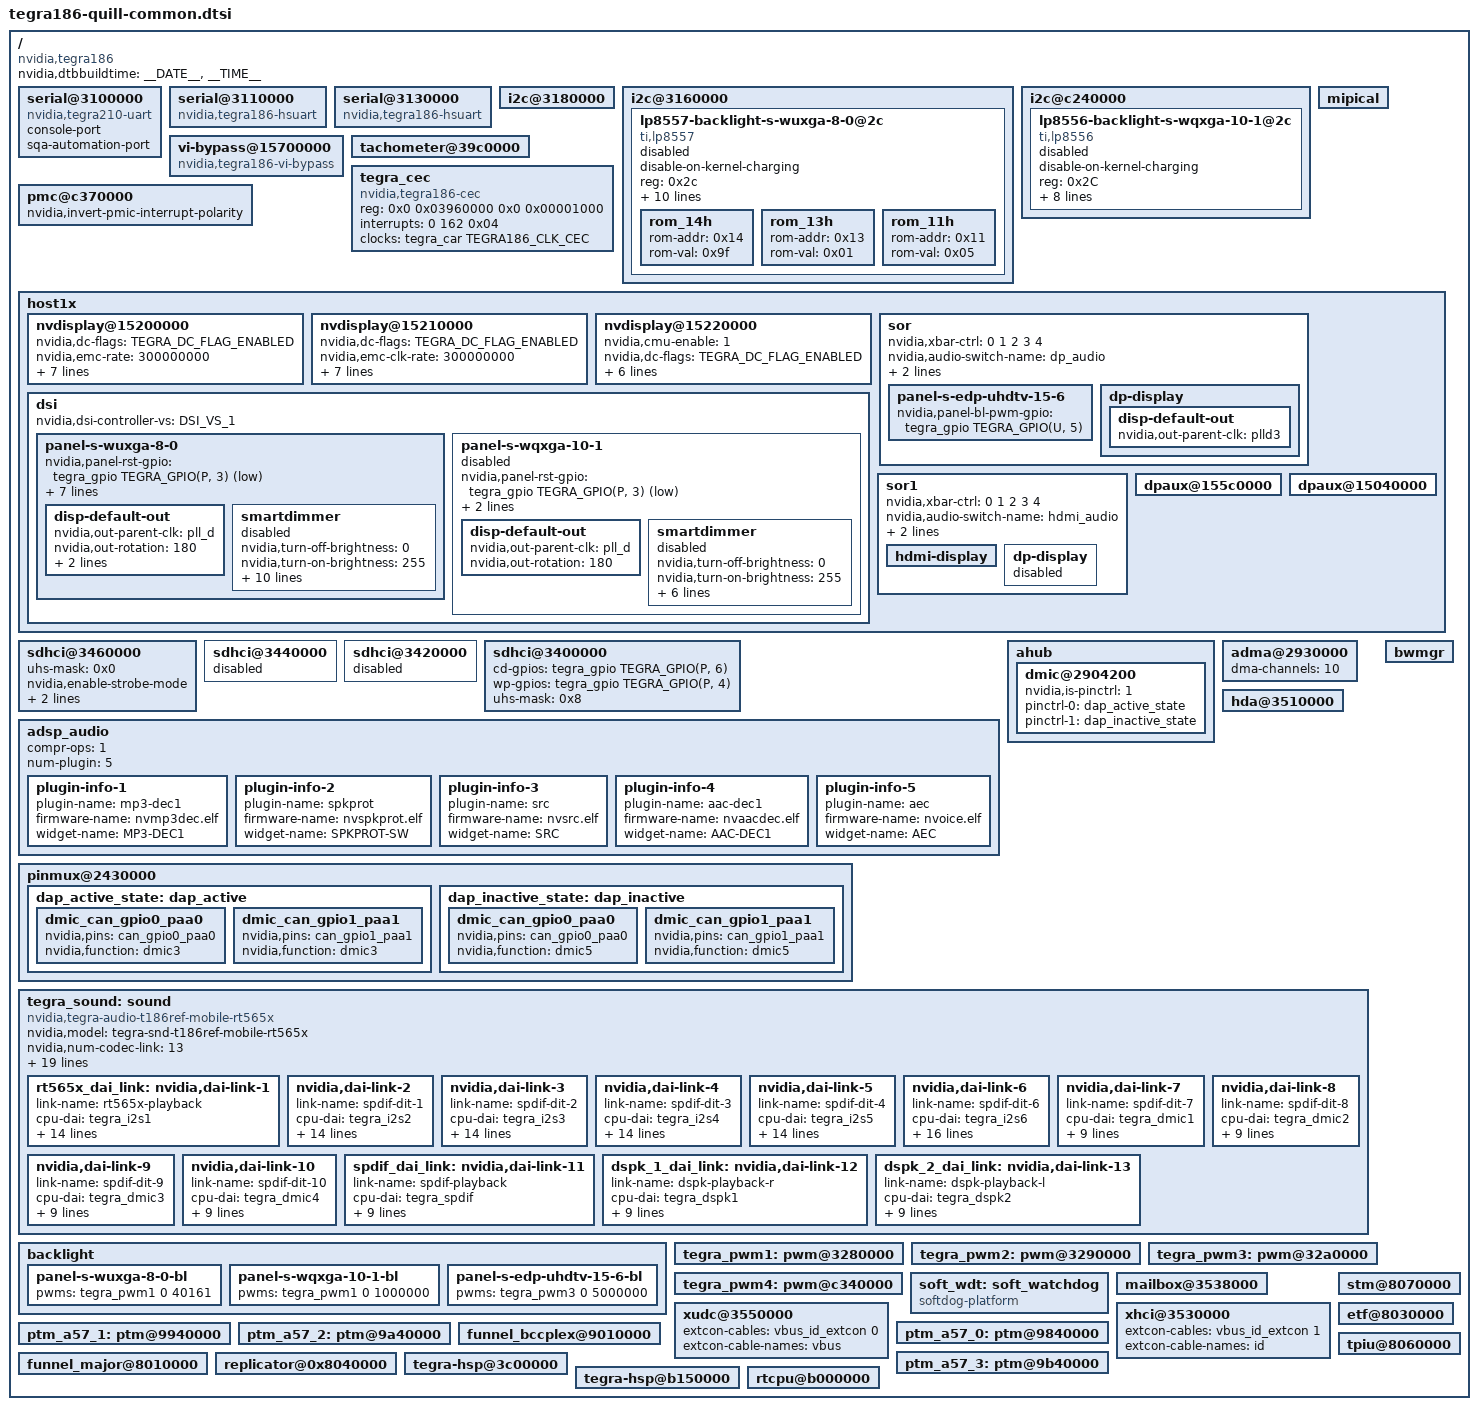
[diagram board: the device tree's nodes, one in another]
/*
 * tegra186-quill-common.dtsi: Quill common dtsi.
 *
 * Copyright (c) 2015-2016, NVIDIA CORPORATION.  All rights reserved.
 *
 * This program is free software; you can redistribute it and/or modify
 * it under the terms of the GNU General Public License as published by
 * the Free Software Foundation; version 2 of the License.
 *
 * This program is distributed in the hope that it will be useful, but WITHOUT
 * ANY WARRANTY; without even the implied warranty of MERCHANTABILITY or
 * FITNESS FOR A PARTICULAR PURPOSE.  See the GNU General Public License for
 * more details.
 */

#include <dt-bindings/types.h>
#include <dt-bindings/gpio/tegra-gpio.h>
/dts-v1/;

/memreserve/ 0x80000000 0x00010000;

#include "tegra186-soc/tegra186-soc-cvm.dtsi"
#include "tegra186-platforms-simple-bus.dtsi"
#include "panel-s-wuxga-8-0.dtsi"
#include "panel-s-wqxga-10-1.dtsi"
#include "tegra186-platforms/tegra186-quill-eqos.dtsi"
#include "tegra186-hdmi.dtsi"
#include "tegra186-dp.dtsi"
#include "panel-s-edp-uhdtv-15-6.dtsi"
#include "tegra186-quill-pwm-fan.dtsi"
#include "tegra186-quill-thermal-fan-est.dtsi"

/ {
        compatible = "nvidia,tegra186";

        nvidia,dtbbuildtime = __DATE__, __TIME__;
        #address-cells = <2>;
        #size-cells = <2>;

	serial@3100000 {
		compatible = "nvidia,tegra210-uart", "nvidia,tegra186-hsuart";
		console-port;
		sqa-automation-port;
		status = "okay";
	};

	serial@3110000 {
		compatible = "nvidia,tegra186-hsuart";
		status = "okay";
	};

	serial@3130000 {
		compatible = "nvidia,tegra186-hsuart";
		dma-names = "tx";
		status = "okay";
	};

	i2c@3180000 {
		status = "okay";
	};

	i2c@3160000 {
		status = "okay";
		lp8557-backlight-s-wuxga-8-0@2c {
			status = "disabled";
			disable-on-kernel-charging;
			compatible = "ti,lp8557";
			reg = <0x2c>;

			bl-name = "pwm-backlight"; /* Match liblights naming expectations */
			init-brt = /bits/ 8 <0xFF>; /* Max brightness */
			dev-ctrl = /bits/ 8 <0x80>; /* PWM, enable standby mode */
			pwm-period = <40161>;

			pwm-names = "lp8557";
			pwms = <&tegra_pwm1 0 40161>;

			bl-measured = < 0 1 2 3 4 5 5 6
					7 8 9 10 11 11 12 13
					14 15 15 16 17 18 19 20
					21 22 22 23 24 25 26 27
					28 29 30 31 31 32 33 34
					35 36 37 37 38 39 40 41
					41 42 43 44 45 46 47 48
					48 49 50 51 52 53 54 54
					55 56 57 58 58 59 60 61
					62 63 64 65 66 67 68 69
					70 71 72 73 74 75 75 76
					77 78 79 80 81 82 83 84
					85 86 87 88 89 90 91 92
					93 94 94 95 96 97 98 99
					100 101 102 104 105 106 107 108
					109 110 111 112 113 114 115 116
					117 118 119 120 121 122 123 125
					126 127 128 129 130 131 132 133
					134 135 136 137 138 139 140 141
					142 143 144 146 147 148 149 150
					151 152 153 154 155 156 157 158
					159 160 161 162 163 164 165 167
					168 169 170 171 172 173 174 175
					176 178 179 180 181 182 183 184
					185 186 187 188 189 190 191 192
					193 194 195 196 197 199 200 201
					202 203 204 205 206 207 208 210
					211 212 213 214 215 216 217 219
					220 221 222 223 225 226 227 228
					229 230 231 233 234 235 236 237
					238 239 240 241 242 244 245 246
					247 248 249 250 251 253 254 255 >;

			bl-curve = < 0 1 1 2 2 3 3 4
					4 5 5 6 7 7 8 8
					9 9 10 10 11 11 12 12
					13 14 14 15 15 16 16 17
					17 18 18 19 20 20 21 21
					22 22 23 23 24 24 25 25
					26 27 27 28 28 29 29 30
					30 31 31 32 33 33 34 34
					35 35 36 36 37 37 38 38
					39 40 40 41 41 42 42 43
					43 44 44 45 46 46 47 47
					48 48 49 49 50 50 51 52
					52 53 53 54 54 55 55 56
					56 57 57 58 59 59 60 60
					61 61 62 62 63 63 64 65
					65 66 66 67 67 68 68 69
					69 70 70 71 72 72 73 73
					74 74 75 75 76 76 77 78
					78 79 79 80 80 81 81 82
					82 83 83 84 85 85 86 86
					87 87 88 88 89 89 90 92
					94 96 97 99 101 103 105 107
					109 110 112 114 116 118 120 122
					123 125 127 129 131 133 134 136
					138 140 142 144 146 147 149 151
					153 155 157 159 160 162 164 166
					168 170 172 173 175 177 179 181
					183 185 186 188 190 192 194 196
					198 199 201 203 205 207 209 211
					212 214 216 218 220 222 223 225
					227 229 231 233 235 236 238 240
					242 244 246 248 249 251 253 255 >;

			/* 5 LED string */
			rom_14h {
				rom-addr = /bits/ 8 <0x14>;
				rom-val = /bits/ 8 <0x9f>;
			};

			/*Boost freq 1MHZ*/
			rom_13h {
				rom-addr = /bits/ 8 <0x13>;
				rom-val = /bits/ 8 <0x01>;
			};

			/*20mA max */
			rom_11h {
				rom-addr = /bits/ 8 <0x11>;
				rom-val = /bits/ 8 <0x05>;
			};
		};
	};

	i2c@c240000 {
		status = "okay";
		lp8556-backlight-s-wqxga-10-1@2c {
			status = "disabled";
			disable-on-kernel-charging;
			compatible = "ti,lp8556";
			reg = <0x2C>;

			bl-name = "pwm-backlight"; /* Match liblights naming expectations */
			init-brt = /bits/ 8 <0xFF>; /* Max brightness */
			dev-ctrl = /bits/ 8 <0x80>; /* PWM, enable standby mode */
			pwm-period = <40161>;

			pwm-names = "lp8556";
			pwms = <&tegra_pwm1 0 40161>;

			bl-measured = < 0 1 2 3 4 5 5 6
					7 8 9 10 11 11 12 13
					14 15 15 16 17 18 19 20
					21 22 22 23 24 25 26 27
					28 29 30 31 31 32 33 34
					35 36 37 37 38 39 40 41
					41 42 43 44 45 46 47 48
					48 49 50 51 52 53 54 54
					55 56 57 58 58 59 60 61
					62 63 64 65 66 67 68 69
					70 71 72 73 74 75 75 76
					77 78 79 80 81 82 83 84
					85 86 87 88 89 90 91 92
					93 94 94 95 96 97 98 99
					100 101 102 104 105 106 107 108
					109 110 111 112 113 114 115 116
					117 118 119 120 121 122 123 125
					126 127 128 129 130 131 132 133
					134 135 136 137 138 139 140 141
					142 143 144 146 147 148 149 150
					151 152 153 154 155 156 157 158
					159 160 161 162 163 164 165 167
					168 169 170 171 172 173 174 175
					176 178 179 180 181 182 183 184
					185 186 187 188 189 190 191 192
					193 194 195 196 197 199 200 201
					202 203 204 205 206 207 208 210
					211 212 213 214 215 216 217 219
					220 221 222 223 225 226 227 228
					229 230 231 233 234 235 236 237
					238 239 240 241 242 244 245 246
					247 248 249 250 251 253 254 255 >;
		};

	};

	vi-bypass@15700000{
		compatible = "nvidia,tegra186-vi-bypass";
		status = "okay";
	};

	tachometer@39c0000 {
		status = "okay";
	};

	tegra_cec {
		status = "okay";
		compatible = "nvidia,tegra186-cec";
		reg = <0x0 0x03960000 0x0 0x00001000>;
		interrupts = <0 162 0x04>;
		clocks = <&tegra_car TEGRA186_CLK_CEC>;
		clock-names = "cec";
	};

	pmc@c370000 {
		nvidia,invert-pmic-interrupt-polarity;
	};

        mipical {
                status = "okay";
        };

	host1x {
		nvdisplay@15200000 {
                        status = "okay";
                        nvidia,dc-flags = <TEGRA_DC_FLAG_ENABLED>;
                        nvidia,emc-rate = <300000000>;
                        nvidia,fb-bpp = <32>;
                        nvidia,fb-flags = <TEGRA_FB_FLIP_ON_PROBE>;
			nvidia,fb-win = <0>;
			win-mask = <0x7>;
			nvidia,dc-ctrlnum = <0>;
			nvidia,dc-or-node = "/host1x/dsi";
			nvidia,cmu-enable = <1>;
                };

		nvdisplay@15210000 {
			status = "okay";
			nvidia,dc-flags = <TEGRA_DC_FLAG_ENABLED>;
			nvidia,emc-clk-rate = <300000000>;
			nvidia,fb-bpp = <32>; /* bits per pixel */
			nvidia,fb-flags = <TEGRA_FB_FLIP_ON_PROBE>;
			nvidia,fb-win = <3>;
			win-mask = <0x38>;
			nvidia,dc-ctrlnum = <1>;
			nvidia,dc-or-node = "/host1x/sor1";
			nvidia,cmu-enable = <1>;
		};

		nvdisplay@15220000 {
			nvidia,cmu-enable = <1>;
		};

		nvdisplay@15220000 {
			status = "okay";
			nvidia,dc-flags = <TEGRA_DC_FLAG_ENABLED>;
			nvidia,emc-clk-rate = <300000000>;
			nvidia,fb-bpp = <32>; /* bits per pixel */
			nvidia,fb-flags = <TEGRA_FB_FLIP_ON_PROBE>;
			win-mask = <0x0>;
			nvidia,dc-ctrlnum = <2>;
			nvidia,dc-or-node = "/host1x/sor";
		};

		dsi {	/* dsi@15300000 */
			nvidia,dsi-controller-vs = <DSI_VS_1>;
			status = "okay";
			panel-s-wuxga-8-0 {
				status = "okay";
				nvidia,panel-rst-gpio = <&tegra_gpio TEGRA_GPIO(P, 3) 1>; /* PP3 */
				nvidia,panel-bl-pwm-gpio = <&tegra_gpio TEGRA_GPIO(U, 0) 1>; /* PU0 */
				nvidia,panel-bl-en-gpio = <&tegra_gpio TEGRA_GPIO(U, 3) 1>; /* PU3 */
				nvidia,panel-en-gpio = <&gpio_i2c_0_77 4 1>; /* tca9539 0x77 Pin 4 */
				nvidia,en-vmm-vpp-with-i2c-config;
				nvidia,default_color_space = <0>;
				disp-default-out {
					nvidia,out-parent-clk = "pll_d";
					nvidia,out-rotation = <180>;
					nvidia,out-xres = <4096>;
					nvidia,out-yres = <2160>;
                                };
				smartdimmer {
					status = "disabled";
					nvidia,turn-off-brightness = <0>;
					nvidia,turn-on-brightness = <255>;
					nvidia,sw-update-delay = <0>;
					nvidia,aggressiveness = <5>;
					nvidia,phase-in-settings = <0>;
					nvidia,phase-in-adjustments = <0>;
					nvidia,sd-window-enable = <0>;
					nvidia,bl-device-name = "pwm-backlight";
					nvidia,gain_table = <
						0x4000 0x4000 0x4000 0x4000 0x4000 0x4000 0x4000 0x4000
						0x4000 0x4000 0x4000 0x4000 0x4000 0x4000 0x4000 0x4000
						0x4000 0x4000 0x4000 0x4000 0x4000 0x4000 0x4000 0x4000
						0x4000 0x4000 0x4000 0x4000 0x4000 0x4000 0x4000 0x4000
						0x4144 0x4144 0x4144 0x4144 0x4144 0x4144 0x4144 0x4144
						0x4144 0x4144 0x4144 0x4144 0x4144 0x4144 0x4144 0x4144
						0x4144 0x4144 0x4144 0x4144 0x4144 0x4144 0x4144 0x4144
						0x4144 0x4144 0x4144 0x4144 0x4144 0x4144 0x4144 0x4144
						0x428c 0x428c 0x428c 0x428c 0x428c 0x428c 0x428c 0x428c
						0x428c 0x428c 0x428c 0x428c 0x428c 0x428c 0x428c 0x428c
						0x428c 0x428c 0x428c 0x428c 0x428c 0x428c 0x428c 0x428c
						0x428c 0x428c 0x428c 0x428c 0x428c 0x428c 0x428c 0x4250
						0x43d4 0x43d4 0x43d4 0x43d4 0x43d4 0x43d4 0x43d4 0x43d4
						0x43d4 0x43d4 0x43d4 0x43d4 0x43d4 0x43d4 0x43d4 0x43d4
						0x43d4 0x43d4 0x43d4 0x43d4 0x43d4 0x43d4 0x43d4 0x43d4
						0x43d4 0x43d4 0x43d4 0x43d4 0x43d4 0x43d4 0x43d4 0x42b4
						0x451c 0x451c 0x451c 0x451c 0x451c 0x451c 0x451c 0x451c
						0x451c 0x451c 0x451c 0x451c 0x451c 0x451c 0x451c 0x451c
						0x451c 0x451c 0x451c 0x451c 0x451c 0x451c 0x451c 0x451c
						0x451c 0x451c 0x451c 0x451c 0x451c 0x451c 0x44e0 0x4304
						0x4664 0x4664 0x4664 0x4664 0x4664 0x4664 0x4664 0x4664
						0x4664 0x4664 0x4664 0x4664 0x4664 0x4664 0x4664 0x4664
						0x4664 0x4664 0x4664 0x4664 0x4664 0x4664 0x4664 0x4664
						0x4664 0x4664 0x4664 0x4664 0x4664 0x4660 0x4570 0x4318
						0x47ac 0x47ac 0x47ac 0x47ac 0x47ac 0x47ac 0x47ac 0x47ac
						0x47ac 0x47ac 0x47ac 0x47ac 0x47ac 0x47ac 0x47ac 0x47ac
						0x47ac 0x47ac 0x47ac 0x47ac 0x47ac 0x47ac 0x47ac 0x47ac
						0x47ac 0x47ac 0x47ac 0x47ac 0x47ac 0x4768 0x45e8 0x433c
						0x48f4 0x48f4 0x48f4 0x48f4 0x48f4 0x48f4 0x48f4 0x48f4
						0x48f4 0x48f4 0x48f4 0x48f4 0x48f4 0x48f4 0x48f4 0x48f4
						0x48f4 0x48f4 0x48f4 0x48f4 0x48f4 0x48f4 0x48f4 0x48f4
						0x48f4 0x48f4 0x48f4 0x48f4 0x48f0 0x482c 0x4644 0x4354
						0x4a3c 0x4a3c 0x4a3c 0x4a3c 0x4a3c 0x4a3c 0x4a3c 0x4a3c
						0x4a3c 0x4a3c 0x4a3c 0x4a3c 0x4a3c 0x4a3c 0x4a3c 0x4a3c
						0x4a3c 0x4a3c 0x4a3c 0x4a3c 0x4a3c 0x4a3c 0x4a3c 0x4a3c
						0x4a3c 0x4a3c 0x4a3c 0x4a3c 0x4a00 0x48c4 0x4688 0x4368
						0x4b84 0x4b84 0x4b84 0x4b84 0x4b84 0x4b84 0x4b84 0x4b84
						0x4b84 0x4b84 0x4b84 0x4b84 0x4b84 0x4b84 0x4b84 0x4b84
						0x4b84 0x4b84 0x4b84 0x4b84 0x4b84 0x4b84 0x4b84 0x4b84
						0x4b84 0x4b84 0x4b84 0x4b84 0x4af4 0x4960 0x46e0 0x4388
						0x4ccc 0x4ccc 0x4ccc 0x4ccc 0x4ccc 0x4ccc 0x4ccc 0x4ccc
						0x4ccc 0x4ccc 0x4ccc 0x4ccc 0x4ccc 0x4ccc 0x4ccc 0x4ccc
						0x4ccc 0x4ccc 0x4ccc 0x4ccc 0x4ccc 0x4ccc 0x4ccc 0x4ccc
						0x4ccc 0x4ccc 0x4ccc 0x4ca8 0x4ba8 0x49c0 0x4708 0x4390
						0x4e14 0x4e14 0x4e14 0x4e14 0x4e14 0x4e14 0x4e14 0x4e14
						0x4e14 0x4e14 0x4e14 0x4e14 0x4e14 0x4e14 0x4e14 0x4e14
						0x4e14 0x4e14 0x4e14 0x4e14 0x4e14 0x4e14 0x4e14 0x4e14
						0x4e14 0x4e14 0x4e14 0x4db0 0x4c60 0x4a34 0x4748 0x43ac
						0x4f5c 0x4f5c 0x4f5c 0x4f5c 0x4f5c 0x4f5c 0x4f5c 0x4f5c
						0x4f5c 0x4f5c 0x4f5c 0x4f5c 0x4f5c 0x4f5c 0x4f5c 0x4f5c
						0x4f5c 0x4f5c 0x4f5c 0x4f5c 0x4f5c 0x4f5c 0x4f5c 0x4f5c
						0x4f5c 0x4f5c 0x4f48 0x4e78 0x4cd4 0x4a6c 0x475c 0x43ac
						0x50a0 0x50a0 0x50a0 0x50a0 0x50a0 0x50a0 0x50a0 0x50a0
						0x50a0 0x50a0 0x50a0 0x50a0 0x50a0 0x50a0 0x50a0 0x50a0
						0x50a0 0x50a0 0x50a0 0x50a0 0x50a0 0x50a0 0x50a0 0x50a0
						0x50a0 0x50a0 0x5060 0x4f44 0x4d60 0x4ac4 0x478c 0x43c0
						0x51e8 0x51e8 0x51e8 0x51e8 0x51e8 0x51e8 0x51e8 0x51e8
						0x51e8 0x51e8 0x51e8 0x51e8 0x51e8 0x51e8 0x51e8 0x51e8
						0x51e8 0x51e8 0x51e8 0x51e8 0x51e8 0x51e8 0x51e8 0x51e8
						0x51e8 0x51e8 0x5158 0x4ff8 0x4dd8 0x4b14 0x47b4 0x43d0
						0x5330 0x5330 0x5330 0x5330 0x5330 0x5330 0x5330 0x5330
						0x5330 0x5330 0x5330 0x5330 0x5330 0x5330 0x5330 0x5330
						0x5330 0x5330 0x5330 0x5330 0x5330 0x5330 0x5330 0x5330
						0x5330 0x5314 0x5238 0x5098 0x4e44 0x4b54 0x47d8 0x43dc
						0x5478 0x5478 0x5478 0x5478 0x5478 0x5478 0x5478 0x5478
						0x5478 0x5478 0x5478 0x5478 0x5478 0x5478 0x5478 0x5478
						0x5478 0x5478 0x5478 0x5478 0x5478 0x5478 0x5478 0x5478
						0x5478 0x5424 0x5300 0x5124 0x4ea4 0x4b90 0x47f8 0x43e8
						0x55c0 0x55c0 0x55c0 0x55c0 0x55c0 0x55c0 0x55c0 0x55c0
						0x55c0 0x55c0 0x55c0 0x55c0 0x55c0 0x55c0 0x55c0 0x55c0
						0x55c0 0x55c0 0x55c0 0x55c0 0x55c0 0x55c0 0x55c0 0x55c0
						0x55b8 0x5518 0x53b4 0x51a4 0x4ef8 0x4bc4 0x4814 0x43f0
						0x5708 0x5708 0x5708 0x5708 0x5708 0x5708 0x5708 0x5708
						0x5708 0x5708 0x5708 0x5708 0x5708 0x5708 0x5708 0x5708
						0x5708 0x5708 0x5708 0x5708 0x5708 0x5708 0x5708 0x5708
						0x56dc 0x55f4 0x5458 0x5214 0x4f44 0x4bf0 0x4828 0x43f8
						0x5850 0x5850 0x5850 0x5850 0x5850 0x5850 0x5850 0x5850
						0x5850 0x5850 0x5850 0x5850 0x5850 0x5850 0x5850 0x5850
						0x5850 0x5850 0x5850 0x5850 0x5850 0x5850 0x5850 0x5850
						0x57e8 0x56bc 0x54e8 0x527c 0x4f88 0x4c18 0x483c 0x4400
						0x5998 0x5998 0x5998 0x5998 0x5998 0x5998 0x5998 0x5998
						0x5998 0x5998 0x5998 0x5998 0x5998 0x5998 0x5998 0x5998
						0x5998 0x5998 0x5998 0x5998 0x5998 0x5998 0x5998 0x5990
						0x58f4 0x579c 0x559c 0x5308 0x4ff4 0x4c64 0x486c 0x4414
						0x5ae0 0x5ae0 0x5ae0 0x5ae0 0x5ae0 0x5ae0 0x5ae0 0x5ae0
						0x5ae0 0x5ae0 0x5ae0 0x5ae0 0x5ae0 0x5ae0 0x5ae0 0x5ae0
						0x5ae0 0x5ae0 0x5ae0 0x5ae0 0x5ae0 0x5ae0 0x5ae0 0x5ab8
						0x59d4 0x5840 0x5614 0x5358 0x5024 0x4c80 0x4878 0x4418
						0x5c28 0x5c28 0x5c28 0x5c28 0x5c28 0x5c28 0x5c28 0x5c28
						0x5c28 0x5c28 0x5c28 0x5c28 0x5c28 0x5c28 0x5c28 0x5c28
						0x5c28 0x5c28 0x5c28 0x5c28 0x5c28 0x5c28 0x5c28 0x5bd8
						0x5ac4 0x5908 0x56b4 0x53d8 0x5084 0x4cc4 0x48a4 0x4428
						0x5d70 0x5d70 0x5d70 0x5d70 0x5d70 0x5d70 0x5d70 0x5d70
						0x5d70 0x5d70 0x5d70 0x5d70 0x5d70 0x5d70 0x5d70 0x5d70
						0x5d70 0x5d70 0x5d70 0x5d70 0x5d70 0x5d70 0x5d68 0x5cd0
						0x5b80 0x5990 0x5714 0x5418 0x50a8 0x4cd8 0x48ac 0x442c
						0x5eb8 0x5eb8 0x5eb8 0x5eb8 0x5eb8 0x5eb8 0x5eb8 0x5eb8
						0x5eb8 0x5eb8 0x5eb8 0x5eb8 0x5eb8 0x5eb8 0x5eb8 0x5eb8
						0x5eb8 0x5eb8 0x5eb8 0x5eb8 0x5eb8 0x5eb8 0x5e9c 0x5dd4
						0x5c58 0x5a40 0x57a0 0x5484 0x50fc 0x4d10 0x48cc 0x443c
						0x6000 0x6000 0x6000 0x6000 0x6000 0x6000 0x6000 0x6000
						0x6000 0x6000 0x6000 0x6000 0x6000 0x6000 0x6000 0x6000
						0x6000 0x6000 0x6000 0x6000 0x6000 0x6000 0x5fc4 0x5ecc
						0x5d24 0x5ae8 0x5828 0x54ec 0x514c 0x4d48 0x48f0 0x4448
						0x6144 0x6144 0x6144 0x6144 0x6144 0x6144 0x6144 0x6144
						0x6144 0x6144 0x6144 0x6144 0x6144 0x6144 0x6144 0x6144
						0x6144 0x6144 0x6144 0x6144 0x6144 0x6144 0x60c4 0x5f8c
						0x5db4 0x5b50 0x586c 0x5518 0x5160 0x4d50 0x48f0 0x4448
						0x628c 0x628c 0x628c 0x628c 0x628c 0x628c 0x628c 0x628c
						0x628c 0x628c 0x628c 0x628c 0x628c 0x628c 0x628c 0x628c
						0x628c 0x628c 0x628c 0x628c 0x628c 0x6280 0x61cc 0x606c
						0x5e6c 0x5be4 0x58e0 0x5574 0x51a4 0x4d80 0x490c 0x4454
						0x63d4 0x63d4 0x63d4 0x63d4 0x63d4 0x63d4 0x63d4 0x63d4
						0x63d4 0x63d4 0x63d4 0x63d4 0x63d4 0x63d4 0x63d4 0x63d4
						0x63d4 0x63d4 0x63d4 0x63d4 0x63d4 0x63ac 0x62cc 0x6140
						0x5f1c 0x5c70 0x5950 0x55cc 0x51e4 0x4dac 0x4928 0x4460
						0x651c 0x651c 0x651c 0x651c 0x651c 0x651c 0x651c 0x651c
						0x651c 0x651c 0x651c 0x651c 0x651c 0x651c 0x651c 0x651c
						0x651c 0x651c 0x651c 0x651c 0x651c 0x64cc 0x63c0 0x6208
						0x5fc0 0x5cf8 0x59bc 0x561c 0x5220 0x4dd4 0x4940 0x446c
						0x6664 0x6664 0x6664 0x6664 0x6664 0x6664 0x6664 0x6664
						0x6664 0x6664 0x6664 0x6664 0x6664 0x6664 0x6664 0x6664
						0x6664 0x6664 0x6664 0x6664 0x6664 0x65e0 0x64a4 0x62c8
						0x605c 0x5d78 0x5a20 0x5668 0x525c 0x4dfc 0x4958 0x4474
						0x67ac 0x67ac 0x67ac 0x67ac 0x67ac 0x67ac 0x67ac 0x67ac
						0x67ac 0x67ac 0x67ac 0x67ac 0x67ac 0x67ac 0x67ac 0x67ac
						0x67ac 0x67ac 0x67ac 0x67ac 0x679c 0x66e8 0x6584 0x6380
						0x60f4 0x5df0 0x5a80 0x56b0 0x5290 0x4e20 0x4970 0x4480
						0x68f4 0x68f4 0x68f4 0x68f4 0x68f4 0x68f4 0x68f4 0x68f4
						0x68f4 0x68f4 0x68f4 0x68f4 0x68f4 0x68f4 0x68f4 0x68f4
						0x68f4 0x68f4 0x68f4 0x68f4 0x68c8 0x67e8 0x6654 0x642c
						0x6180 0x5e60 0x5ad8 0x56f4 0x52c0 0x4e44 0x4984 0x4488
						0x6a3c 0x6a3c 0x6a3c 0x6a3c 0x6a3c 0x6a3c 0x6a3c 0x6a3c
						0x6a3c 0x6a3c 0x6a3c 0x6a3c 0x6a3c 0x6a3c 0x6a3c 0x6a3c
						0x6a3c 0x6a3c 0x6a3c 0x6a3c 0x69ec 0x68d8 0x6720 0x64d4
						0x6208 0x5ecc 0x5b2c 0x5734 0x52f0 0x4e60 0x4994 0x4490
						0x6b84 0x6b84 0x6b84 0x6b84 0x6b84 0x6b84 0x6b84 0x6b84
						0x6b84 0x6b84 0x6b84 0x6b84 0x6b84 0x6b84 0x6b84 0x6b84
						0x6b84 0x6b84 0x6b84 0x6b80 0x6b00 0x69c0 0x67e0 0x6570
						0x6288 0x5f30 0x5b7c 0x5770 0x531c 0x4e80 0x49a8 0x4494
						0x6ccc 0x6ccc 0x6ccc 0x6ccc 0x6ccc 0x6ccc 0x6ccc 0x6ccc
						0x6ccc 0x6ccc 0x6ccc 0x6ccc 0x6ccc 0x6ccc 0x6ccc 0x6ccc
						0x6ccc 0x6ccc 0x6ccc 0x6cc4 0x6c24 0x6acc 0x68d0 0x6648
						0x6344 0x5fd8 0x5c08 0x57e4 0x5378 0x4ec4 0x49d4 0x44ac
						0x6e14 0x6e14 0x6e14 0x6e14 0x6e14 0x6e14 0x6e14 0x6e14
						0x6e14 0x6e14 0x6e14 0x6e14 0x6e14 0x6e14 0x6e14 0x6e14
						0x6e14 0x6e14 0x6e14 0x6df8 0x6d28 0x6ba0 0x6980 0x66d8
						0x63b8 0x6034 0x5c50 0x5818 0x539c 0x4edc 0x49e0 0x44b0
						0x6f5c 0x6f5c 0x6f5c 0x6f5c 0x6f5c 0x6f5c 0x6f5c 0x6f5c
						0x6f5c 0x6f5c 0x6f5c 0x6f5c 0x6f5c 0x6f5c 0x6f5c 0x6f5c
						0x6f5c 0x6f5c 0x6f5c 0x6f1c 0x6e1c 0x6c6c 0x6a28 0x6760
						0x6428 0x6088 0x5c90 0x584c 0x53c0 0x4ef4 0x49ec 0x44b4
						0x70a0 0x70a0 0x70a0 0x70a0 0x70a0 0x70a0 0x70a0 0x70a0
						0x70a0 0x70a0 0x70a0 0x70a0 0x70a0 0x70a0 0x70a0 0x70a0
						0x70a0 0x70a0 0x70a0 0x7034 0x6f04 0x6d30 0x6ac8 0x67e0
						0x648c 0x60d8 0x5cd0 0x5878 0x53e0 0x4f08 0x49f8 0x44bc
						0x71e8 0x71e8 0x71e8 0x71e8 0x71e8 0x71e8 0x71e8 0x71e8
						0x71e8 0x71e8 0x71e8 0x71e8 0x71e8 0x71e8 0x71e8 0x71e8
						0x71e8 0x71e8 0x71e8 0x7160 0x7014 0x6e24 0x6ba4 0x68a4
						0x6538 0x616c 0x5d4c 0x58e0 0x5430 0x4f44 0x4a20 0x44cc
						0x7330 0x7330 0x7330 0x7330 0x7330 0x7330 0x7330 0x7330
						0x7330 0x7330 0x7330 0x7330 0x7330 0x7330 0x7330 0x7330
						0x7330 0x7330 0x7320 0x7264 0x70ec 0x6ed4 0x6c34 0x6918
						0x6594 0x61b4 0x5d84 0x5908 0x544c 0x4f54 0x4a2c 0x44d0
						0x7478 0x7478 0x7478 0x7478 0x7478 0x7478 0x7478 0x7478
						0x7478 0x7478 0x7478 0x7478 0x7478 0x7478 0x7478 0x7478
						0x7478 0x7478 0x745c 0x7384 0x71f0 0x6fc0 0x6d04 0x69d4
						0x6638 0x6244 0x5dfc 0x5968 0x5498 0x4f90 0x4a50 0x44e0
						0x75c0 0x75c0 0x75c0 0x75c0 0x75c0 0x75c0 0x75c0 0x75c0
						0x75c0 0x75c0 0x75c0 0x75c0 0x75c0 0x75c0 0x75c0 0x75c0
						0x75c0 0x75c0 0x7580 0x7474 0x72b8 0x7064 0x6d88 0x6a3c
						0x668c 0x6280 0x5e28 0x598c 0x54b0 0x4f9c 0x4a58 0x44e4
						0x7708 0x7708 0x7708 0x7708 0x7708 0x7708 0x7708 0x7708
						0x7708 0x7708 0x7708 0x7708 0x7708 0x7708 0x7708 0x7708
						0x7708 0x7708 0x76b0 0x758c 0x73b4 0x7144 0x6e54 0x6af0
						0x6728 0x6308 0x5e9c 0x59e8 0x54f8 0x4fd4 0x4a78 0x44f4
						0x7850 0x7850 0x7850 0x7850 0x7850 0x7850 0x7850 0x7850
						0x7850 0x7850 0x7850 0x7850 0x7850 0x7850 0x7850 0x7850
						0x7850 0x7850 0x77c0 0x766c 0x746c 0x71d8 0x6ec8 0x6b4c
						0x6770 0x6340 0x5ec4 0x5a04 0x550c 0x4fdc 0x4a80 0x44f8
						0x7998 0x7998 0x7998 0x7998 0x7998 0x7998 0x7998 0x7998
						0x7998 0x7998 0x7998 0x7998 0x7998 0x7998 0x7998 0x7998
						0x7998 0x7990 0x78e4 0x7774 0x755c 0x72b0 0x6f88 0x6bf8
						0x6804 0x63c0 0x5f30 0x5a5c 0x5550 0x5010 0x4aa0 0x4504
						0x7ae0 0x7ae0 0x7ae0 0x7ae0 0x7ae0 0x7ae0 0x7ae0 0x7ae0
						0x7ae0 0x7ae0 0x7ae0 0x7ae0 0x7ae0 0x7ae0 0x7ae0 0x7ae0
						0x7ae0 0x7ac0 0x79e0 0x7844 0x7604 0x7338 0x6ff4 0x6c48
						0x6844 0x63ec 0x5f50 0x5a74 0x5560 0x5018 0x4aa4 0x4508
						0x7c28 0x7c28 0x7c28 0x7c28 0x7c28 0x7c28 0x7c28 0x7c28
						0x7c28 0x7c28 0x7c28 0x7c28 0x7c28 0x7c28 0x7c28 0x7c28
						0x7c28 0x7bf8 0x7afc 0x7940 0x76e8 0x7404 0x70ac 0x6cec
						0x68d0 0x6468 0x5fb8 0x5ac8 0x55a0 0x5048 0x4ac4 0x4514
						0x7d70 0x7d70 0x7d70 0x7d70 0x7d70 0x7d70 0x7d70 0x7d70
						0x7d70 0x7d70 0x7d70 0x7d70 0x7d70 0x7d70 0x7d70 0x7d70
						0x7d70 0x7d2c 0x7c10 0x7a3c 0x77cc 0x74d0 0x7160 0x6d8c
						0x695c 0x64dc 0x601c 0x5b18 0x55e0 0x5078 0x4ae0 0x4524
						0x7eb8 0x7eb8 0x7eb8 0x7eb8 0x7eb8 0x7eb8 0x7eb8 0x7eb8
						0x7eb8 0x7eb8 0x7eb8 0x7eb8 0x7eb8 0x7eb8 0x7eb8 0x7eb8
						0x7eb8 0x7e40 0x7cf4 0x7af4 0x785c 0x7544 0x71bc 0x6dd0
						0x6990 0x6504 0x6034 0x5b28 0x55ec 0x507c 0x4ae4 0x4524
						0x8000 0x8000 0x8000 0x8000 0x8000 0x8000 0x8000 0x8000
						0x8000 0x8000 0x8000 0x8000 0x8000 0x8000 0x8000 0x8000
						0x7ffc 0x7f68 0x7e00 0x7be4 0x7938 0x7608 0x7268 0x6e68
						0x6a14 0x6574 0x6094 0x5b78 0x5628 0x50a8 0x4b00 0x4530
					>;
					nvidia,backlight_table = <
						255 243 232 222 212 203 194 186 179 171 165 158 152
						146 141 136 131 126 122 118 114 110 106 103 100 96
						93 90 88 85 83 80 78 76 73 71 69 67 66 64 62 61 59
						58 56 55 53 52 51 49 48
					>;
				};
			};
			panel-s-wqxga-10-1 {
				status = "disabled";
				nvidia,panel-rst-gpio = <&tegra_gpio TEGRA_GPIO(P, 3) 1>; /* PP3 */
				nvidia,panel-bl-pwm-gpio = <&tegra_gpio TEGRA_GPIO(U, 0) 1>; /* PU0 */
				disp-default-out {
					nvidia,out-parent-clk = "pll_d";
					nvidia,out-rotation = <180>;
				};
				smartdimmer {
					status = "disabled";
					nvidia,turn-off-brightness = <0>;
					nvidia,turn-on-brightness = <255>;
					nvidia,sw-update-delay = <0>;
					nvidia,aggressiveness = <5>;
					nvidia,phase-in-settings = <0>;
					nvidia,phase-in-adjustments = <0>;
					nvidia,sd-window-enable = <0>;
					nvidia,bl-device-name = "pwm-backlight";
				};
			};
		};

		sor{
			status = "okay";
			nvidia,xbar-ctrl = <0 1 2 3 4>;
			nvidia,audio-switch-name = "dp_audio";
			nvidia,hpd-gpio = <&tegra_gpio TEGRA_GPIO(P, 0) GPIO_ACTIVE_LOW>;
			panel-s-edp-uhdtv-15-6 {
				nvidia,panel-bl-pwm-gpio = <&tegra_gpio TEGRA_GPIO(U, 5) 0>;
			};

			dp-display {
				disp-default-out {
					nvidia,out-parent-clk = "plld3";
				};
			};
		};
		sor1 {
			status = "okay";
			nvidia,xbar-ctrl = <0 1 2 3 4>;
			nvidia,audio-switch-name = "hdmi_audio";
			nvidia,hpd-gpio = <&tegra_gpio TEGRA_GPIO(P, 1) GPIO_ACTIVE_LOW>;
			hdmi-display {
				status = "okay";
			};

			dp-display {
				status = "disabled";
			};
		};
		dpaux@155c0000 {
			status = "okay";
		};
		dpaux@15040000 {
			status = "okay";
		};
	};

	sdhci@3460000 {
		uhs-mask = <0x0>; /*enable HS400 mode*/
		nvidia,enable-strobe-mode;
		nvidia,en-periodic-cflush;
		nvidia,periodic-cflush-to = <100>;
		status = "okay";
	};

	sdhci@3440000 {
		status = "disabled";
	};

	sdhci@3420000 {
		status = "disabled";
	};

	sdhci@3400000 {
		cd-gpios = <&tegra_gpio TEGRA_GPIO(P, 6) 0>;
		wp-gpios = <&tegra_gpio TEGRA_GPIO(P, 4) 0>;
		uhs-mask = <0x8>;
		status = "okay";
	};

	adsp_audio {
		compr-ops = <1>;
		num-plugin = <5>;
		plugin-info-1 {
			plugin-name = "mp3-dec1";
			firmware-name = "nvmp3dec.elf";
			widget-name = "MP3-DEC1";
		};
		plugin-info-2 {
			plugin-name = "spkprot";
			firmware-name = "nvspkprot.elf";
			widget-name = "SPKPROT-SW";
		};
		plugin-info-3 {
			plugin-name = "src";
			firmware-name = "nvsrc.elf";
			widget-name = "SRC";
		};
		plugin-info-4 {
			plugin-name = "aac-dec1";
			firmware-name = "nvaacdec.elf";
			widget-name = "AAC-DEC1";
		};
		plugin-info-5 {
			plugin-name = "aec";
			firmware-name = "nvoice.elf";
			widget-name = "AEC";
		};
	};

	pinmux@2430000 {
		dap_active_state: dap_active {
			dmic_can_gpio0_paa0 {
				nvidia,pins = "can_gpio0_paa0";
				nvidia,function = "dmic3";
			};
			dmic_can_gpio1_paa1 {
				nvidia,pins = "can_gpio1_paa1";
				nvidia,function = "dmic3";
			};
		};
		dap_inactive_state: dap_inactive {
			dmic_can_gpio0_paa0 {
				nvidia,pins = "can_gpio0_paa0";
				nvidia,function = "dmic5";
			};
			dmic_can_gpio1_paa1 {
				nvidia,pins = "can_gpio1_paa1";
				nvidia,function = "dmic5";
			};
		};
	};

	ahub {
		dmic@2904200 {
			nvidia,is-pinctrl = <1>;
			pinctrl-names = "dap_active", "dap_inactive";
			pinctrl-0 = <&dap_active_state>;
			pinctrl-1 = <&dap_inactive_state>;
		};
	};

	adma@2930000 {
		dma-channels = <10>;
	};

	hda@3510000 {
		status = "okay";
       };

	tegra_sound: sound {
		compatible = "nvidia,tegra-audio-t186ref-mobile-rt565x";
		nvidia,model = "tegra-snd-t186ref-mobile-rt565x";
		nvidia,num-codec-link = <13>;
		nvidia,num-clk = <8>;
		nvidia,clk-rates = < 270950400	/* PLLA_x11025_RATE */
				     11289600	/* AUD_MCLK_x11025_RATE */
				     45158400	/* PLLA_OUT0_x11025_RATE */
				     45158400	/* AHUB_x11025_RATE */
				     245760000  /* PLLA_x8000_RATE */
				     12288000	/* AUD_MCLK_x8000_RATE */
				     49152000	/* PLLA_OUT0_x8000_RATE */
				     49152000 >;/* AHUB_x8000_RATE */
		clocks = <&tegra_car TEGRA186_CLK_PLLP_OUT0>,
			<&tegra_car TEGRA186_CLK_PLLA>,
			<&tegra_car TEGRA186_CLK_PLL_A_OUT0>,
			<&tegra_car TEGRA186_CLK_AHUB>,
			<&tegra_car TEGRA186_CLK_CLK_M>,
			<&tegra_car TEGRA186_CLK_AUD_MCLK>;
		clock-names = "pll_p_out1", "pll_a", "pll_a_out0", "ahub",
				"clk_m", "extern1";
		resets = <&tegra_car TEGRA186_RESET_AUD_MCLK>;
		reset-names = "extern1_rst";

		status = "okay";
		nvidia,audio-routing =
			"x Headphone",		"x OUT",
			"x IN",			"x Mic",
			"y Headphone",		"y OUT",
			"y IN",			"y Mic",
			"z IN",			"z OUT",
			"m Headphone",		"m OUT",
			"m IN",			"m Mic",
			"n Headphone",		"n OUT",
			"n IN",			"n Mic",
			"o Headphone",		"o OUT",
			"o IN",			"o Mic",
			"a IN",			"a Mic",
			"b IN",			"b Mic",
			"c IN",			"c Mic",
			"d IN",			"d Mic",
			"e Headphone",		"e OUT",
			"e IN",			"e Mic",
			"d1 Headphone",		"d1 OUT",
			"d2 Headphone",		"d2 OUT";

		nvidia,xbar = <&tegra_axbar>;

		rt565x_dai_link: nvidia,dai-link-1 {
			link-name = "rt565x-playback";
			cpu-dai = <&tegra_i2s1>;
			codec-dai = <&spdif_dit0>;
			cpu-dai-name = "I2S1";
			codec-dai-name = "dit-hifi";
			format = "i2s";
			bitclock-slave;
			frame-slave;
			bitclock-noninversion;
			frame-noninversion;
			bit-format = "s16_le";
			bclk_ratio = <0>;
			srate = <48000>;
			num-channel = <2>;
			ignore_suspend;
			name-prefix = "x";
			status = "okay";
		};
		nvidia,dai-link-2 {
			link-name = "spdif-dit-1";
			cpu-dai = <&tegra_i2s2>;
			codec-dai = <&spdif_dit1>;
			cpu-dai-name = "I2S2";
			codec-dai-name = "dit-hifi";
			format = "i2s";
			bitclock-slave;
			frame-slave;
			bitclock-noninversion;
			frame-noninversion;
			bit-format = "s16_le";
			bclk_ratio = <1>;
			srate = <48000>;
			num-channel = <2>;
			ignore_suspend;
			name-prefix = "y";
			status = "okay";
		};
		nvidia,dai-link-3 {
			link-name = "spdif-dit-2";
			cpu-dai = <&tegra_i2s3>;
			codec-dai = <&spdif_dit2>;
			cpu-dai-name = "I2S3";
			codec-dai-name = "dit-hifi";
			format = "i2s";
			bitclock-slave;
			frame-slave;
			bitclock-noninversion;
			frame-noninversion;
			bit-format = "s16_le";
			bclk_ratio = <1>;
			srate = <48000>;
			num-channel = <2>;
			ignore_suspend;
			name-prefix = "z";
			status = "okay";
		};
		nvidia,dai-link-4 {
			link-name = "spdif-dit-3";
			cpu-dai = <&tegra_i2s4>;
			codec-dai = <&spdif_dit3>;
			cpu-dai-name = "I2S4";
			codec-dai-name = "dit-hifi";
			format = "i2s";
			bitclock-slave;
			frame-slave;
			bitclock-noninversion;
			frame-noninversion;
			bit-format = "s16_le";
			bclk_ratio = <1>;
			srate = <48000>;
			num-channel = <2>;
			ignore_suspend;
			name-prefix = "m";
			status = "okay";
		};
		nvidia,dai-link-5 {
			link-name = "spdif-dit-4";
			cpu-dai = <&tegra_i2s5>;
			codec-dai = <&spdif_dit4>;
			cpu-dai-name = "I2S5";
			codec-dai-name = "dit-hifi";
			format = "i2s";
			bitclock-slave;
			frame-slave;
			bitclock-noninversion;
			frame-noninversion;
			bit-format = "s16_le";
			bclk_ratio = <1>;
			srate = <48000>;
			num-channel = <2>;
			ignore_suspend;
			name-prefix = "n";
			status = "okay";
		};
		nvidia,dai-link-6 {
			link-name = "spdif-dit-6";
			cpu-dai = <&tegra_i2s6>;
			codec-dai = <&spdif_dit6>;
			cpu-dai-name = "I2S6";
			codec-dai-name = "dit-hifi";
			tx-mask = <0xFF>;
			rx-mask = <0xFF>;
			format = "dsp_a";
			bitclock-slave;
			frame-slave;
			bitclock-inversion;
			frame-inversion;
			bit-format = "s16_le";
			bclk_ratio = <4>;
			srate = <8000>;
			num-channel = <1>;
			ignore_suspend;
			name-prefix = "o";
			status = "okay";
		};
		nvidia,dai-link-7 {
			link-name = "spdif-dit-7";
			cpu-dai = <&tegra_dmic1>;
			codec-dai = <&spdif_dit7>;
			cpu-dai-name = "DMIC1";
			codec-dai-name = "dit-hifi";
			format = "i2s";
			bit-format = "s16_le";
			srate = <48000>;
			ignore_suspend;
			num-channel = <2>;
			name-prefix = "a";
			status = "okay";
		};
		nvidia,dai-link-8 {
			link-name = "spdif-dit-8";
			cpu-dai = <&tegra_dmic2>;
			codec-dai = <&spdif_dit8>;
			cpu-dai-name = "DMIC2";
			codec-dai-name = "dit-hifi";
			format = "i2s";
			bit-format = "s16_le";
			srate = <48000>;
			ignore_suspend;
			num-channel = <2>;
			name-prefix = "b";
			status = "okay";
		};
		nvidia,dai-link-9 {
			link-name = "spdif-dit-9";
			cpu-dai = <&tegra_dmic3>;
			codec-dai = <&spdif_dit9>;
			cpu-dai-name = "DMIC3";
			codec-dai-name = "dit-hifi";
			format = "i2s";
			bit-format = "s16_le";
			srate = <48000>;
			ignore_suspend;
			num-channel = <2>;
			name-prefix = "c";
			status = "okay";
		};
		nvidia,dai-link-10 {
			link-name = "spdif-dit-10";
			cpu-dai = <&tegra_dmic4>;
			codec-dai = <&spdif_dit10>;
			cpu-dai-name = "DMIC4";
			codec-dai-name = "dit-hifi";
			format = "i2s";
			bit-format = "s16_le";
			srate = <48000>;
			ignore_suspend;
			num-channel = <2>;
			name-prefix = "d";
			status = "okay";
		};
		spdif_dai_link: nvidia,dai-link-11 {
			link-name = "spdif-playback";
			cpu-dai = <&tegra_spdif>;
			codec-dai = <&spdif_dit11>;
			cpu-dai-name = "SPDIF1-1";
			codec-dai-name = "dit-hifi";
			format = "i2s";
			bit-format = "s16_le";
			srate = <48000>;
			num-channel = <2>;
			ignore_suspend;
			name-prefix = "e";
			status = "okay";
		};
		dspk_1_dai_link: nvidia,dai-link-12 {
			link-name = "dspk-playback-r";
			cpu-dai = <&tegra_dspk1>;
			codec-dai = <&spdif_dit12>;
			cpu-dai-name = "DSPK1";
			codec-dai-name = "dit-hifi";
			format = "i2s";
			bit-format = "s16_le";
			srate = <48000>;
			num-channel = <2>;
			ignore_suspend;
			name-prefix = "d1";
			status = "okay";
		};
		dspk_2_dai_link: nvidia,dai-link-13 {
			link-name = "dspk-playback-l";
			cpu-dai = <&tegra_dspk2>;
			codec-dai = <&spdif_dit13>;
			cpu-dai-name = "DSPK2";
			codec-dai-name = "dit-hifi";
			format = "i2s";
			bit-format = "s16_le";
			srate = <48000>;
			num-channel = <2>;
			ignore_suspend;
			name-prefix = "d2";
			status = "okay";
                };
	};

	backlight {
		status = "okay";
		panel-s-wuxga-8-0-bl {
			pwms = <&tegra_pwm1 0 40161>;
		};
		panel-s-wqxga-10-1-bl {
			pwms = <&tegra_pwm1 0 1000000>;
		};
                panel-s-edp-uhdtv-15-6-bl {
                        pwms = <&tegra_pwm3 0 5000000>;
                };
	};

	tegra_pwm1: pwm@3280000 {
		status = "okay";
	};

	tegra_pwm2: pwm@3290000 {
		status = "okay";
	};

	tegra_pwm3: pwm@32a0000 {
		status = "okay";
	};

	tegra_pwm4: pwm@c340000 {
		status = "okay";
	};

	soft_wdt:soft_watchdog {
		compatible = "softdog-platform";
		status = "okay";
	};

	mailbox@3538000 {
		status = "okay";
	};

	xudc@3550000 {
		extcon-cables = <&vbus_id_extcon 0>;
		extcon-cable-names = "vbus";
		#extcon-cells = <1>;
	};

	xhci@3530000 {
		extcon-cables = <&vbus_id_extcon 1>;
		extcon-cable-names = "id";
		#extcon-cells = <1>;
	};

	bwmgr {
		status = "okay";
	};

	stm@8070000 {
		status = "okay";
	};

	ptm_a57_0: ptm@9840000 {
		status = "okay";
	};

	ptm_a57_1: ptm@9940000 {
		status = "okay";
	};

	ptm_a57_2: ptm@9a40000 {
		status = "okay";
	};

	ptm_a57_3: ptm@9b40000 {
		status = "okay";
	};

	funnel_bccplex@9010000 {
		status = "okay";
	};

	funnel_major@8010000 {
		status = "okay";
	};

	replicator@0x8040000 {
		status = "okay";
	};

	etf@8030000 {
		status = "okay";
	};

	tpiu@8060000 {
		status = "okay";
	};

	tegra-hsp@3c00000 {
		status = "okay";
	};

	tegra-hsp@b150000 {
		status = "okay";
	};

	rtcpu@b000000 {
		status = "okay";
	};
};
